# ESP32-P4-LP register map
Vendor: ESPRESSIF SYSTEMS (SHANGHAI) CO., LTD.; Series: ESP32 P-Series; File version: 3
CPU: RV32IMAC r0p0, little endian, no MPU, no FPU, 0 interrupt priority bits
Address unit: 32 bits
Registers are 32-bit, read-write, reset 0x0 unless marked. A register's access mark holds for its fields unless they carry their own. Offsets are from the block's base; [hi:lo] are bit positions.

## LP_ADC — Low-power Analog to Digital Converter
Base 0x50127000
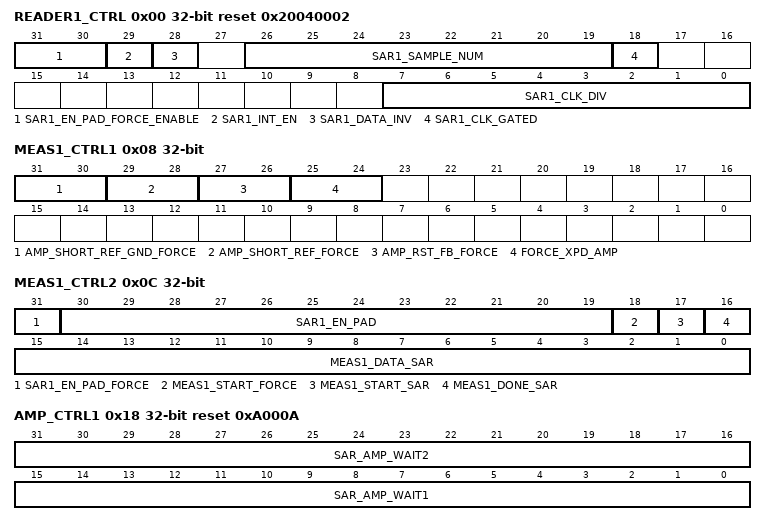
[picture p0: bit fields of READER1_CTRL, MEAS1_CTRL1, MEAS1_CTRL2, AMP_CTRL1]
0x00 READER1_CTRL reset 0x20040002 — Control the read operation of ADC1.
  [31:30] SAR1_EN_PAD_FORCE_ENABLE — Force enable adc en_pad to analog circuit 2'b11: force enable .
  [29] SAR1_INT_EN — Enable saradc1 to send out interrupt.
  [28] SAR1_DATA_INV — Invert SAR ADC1 data.
  [26:19] SAR1_SAMPLE_NUM
  [18] SAR1_CLK_GATED
  [7:0] SAR1_CLK_DIV — Clock divider.
0x04 READER1_STATUS ro reset 0x20000000
  [31:0] SAR1_READER_STATUS
0x08 MEAS1_CTRL1
  [31:30] AMP_SHORT_REF_GND_FORCE, [29:28] AMP_SHORT_REF_FORCE, [27:26] AMP_RST_FB_FORCE, [25:24] FORCE_XPD_AMP
0x0C MEAS1_CTRL2 access per field — ADC1 configuration registers.
  [31] SAR1_EN_PAD_FORCE rw — 1: SAR ADC1 pad enable bitmap is controlled by SW.
  [30:19] SAR1_EN_PAD rw — SAR ADC1 pad enable bitmap.
  [18] MEAS1_START_FORCE rw — 1: SAR ADC1 controller (in RTC) is started by SW.
  [17] MEAS1_START_SAR rw — SAR ADC1 controller (in RTC) starts conversion.
  [16] MEAS1_DONE_SAR ro — SAR ADC1 conversion done indication.
  [15:0] MEAS1_DATA_SAR ro — SAR ADC1 data.
0x10 MEAS1_MUX — SAR ADC1 MUX register.
  [31] SAR1_DIG_FORCE — 1: SAR ADC1 controlled by DIG ADC1 CTRL.
0x14 ATTEN1 reset 0xFFFFFFFF — ADC1 attenuation registers.
  [31:0] SAR1_ATTEN — 2-bit attenuation for each pad.
0x18 AMP_CTRL1 reset 0xA000A
  [31:16] SAR_AMP_WAIT2, [15:0] SAR_AMP_WAIT1
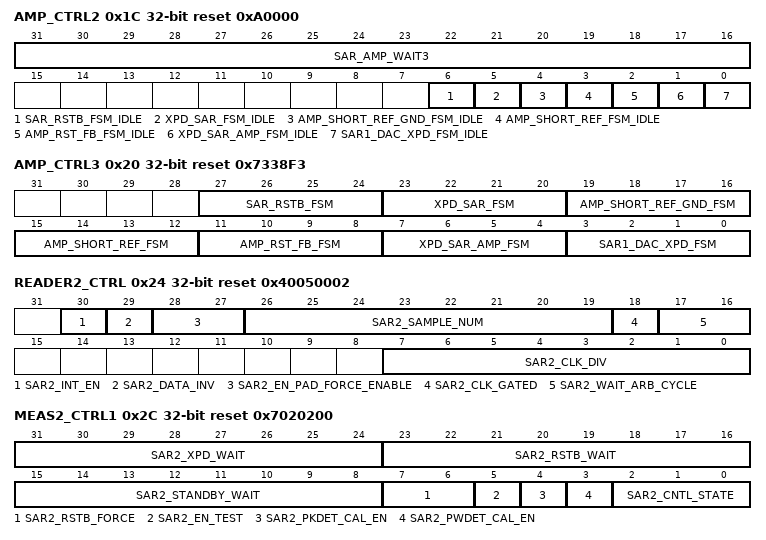
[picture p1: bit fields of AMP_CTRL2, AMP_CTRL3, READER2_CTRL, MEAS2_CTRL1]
0x1C AMP_CTRL2 reset 0xA0000
  [31:16] SAR_AMP_WAIT3, [6] SAR_RSTB_FSM_IDLE, [5] XPD_SAR_FSM_IDLE, [4] AMP_SHORT_REF_GND_FSM_IDLE, [3] AMP_SHORT_REF_FSM_IDLE, [2] AMP_RST_FB_FSM_IDLE, [1] XPD_SAR_AMP_FSM_IDLE, [0] SAR1_DAC_XPD_FSM_IDLE
0x20 AMP_CTRL3 reset 0x7338F3
  [27:24] SAR_RSTB_FSM, [23:20] XPD_SAR_FSM, [19:16] AMP_SHORT_REF_GND_FSM, [15:12] AMP_SHORT_REF_FSM, [11:8] AMP_RST_FB_FSM, [7:4] XPD_SAR_AMP_FSM, [3:0] SAR1_DAC_XPD_FSM
0x24 READER2_CTRL reset 0x40050002 — Control the read operation of ADC2.
  [30] SAR2_INT_EN — Enable saradc2 to send out interrupt.
  [29] SAR2_DATA_INV — Invert SAR ADC2 data.
  [28:27] SAR2_EN_PAD_FORCE_ENABLE — Force enable adc en_pad to analog circuit 2'b11: force enable .
  [26:19] SAR2_SAMPLE_NUM
  [18] SAR2_CLK_GATED
  [17:16] SAR2_WAIT_ARB_CYCLE — Wait arbit stable after sar_done.
  [7:0] SAR2_CLK_DIV — Clock divider.
0x28 READER2_STATUS ro
  [31:0] SAR2_READER_STATUS
0x2C MEAS2_CTRL1 access per field reset 0x7020200 — ADC2 configuration registers.
  [31:24] SAR2_XPD_WAIT rw
  [23:16] SAR2_RSTB_WAIT rw
  [15:8] SAR2_STANDBY_WAIT rw
  [7:6] SAR2_RSTB_FORCE rw
  [5] SAR2_EN_TEST rw
  [4] SAR2_PKDET_CAL_EN rw — RTC control pkdet enable.
  [3] SAR2_PWDET_CAL_EN rw — RTC control pwdet enable.
  [2:0] SAR2_CNTL_STATE ro — saradc2_cntl_fsm.
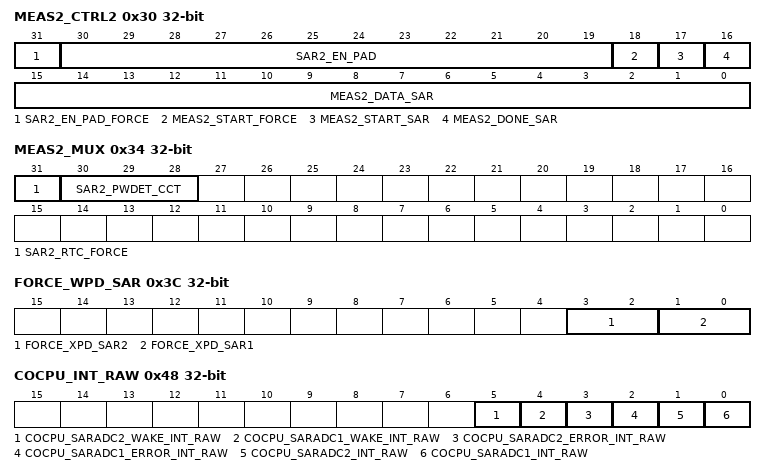
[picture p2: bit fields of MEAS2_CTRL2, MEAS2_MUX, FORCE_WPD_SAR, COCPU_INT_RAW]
0x30 MEAS2_CTRL2 access per field — ADC2 configuration registers.
  [31] SAR2_EN_PAD_FORCE rw — 1: SAR ADC2 pad enable bitmap is controlled by SW.
  [30:19] SAR2_EN_PAD rw — SAR ADC2 pad enable bitmap.
  [18] MEAS2_START_FORCE rw — 1: SAR ADC2 controller (in RTC) is started by SW.
  [17] MEAS2_START_SAR rw — SAR ADC2 controller (in RTC) starts conversion.
  [16] MEAS2_DONE_SAR ro — SAR ADC2 conversion done indication.
  [15:0] MEAS2_DATA_SAR ro — SAR ADC2 data.
0x34 MEAS2_MUX — SAR ADC2 MUX register.
  [31] SAR2_RTC_FORCE — In sleep, force to use rtc to control ADC.
  [30:28] SAR2_PWDET_CCT
0x38 ATTEN2 reset 0xFFFFFFFF — ADC1 attenuation registers.
  [31:0] SAR2_ATTEN — 2-bit attenuation for each pad.
0x3C FORCE_WPD_SAR — In sleep, force to use rtc to control ADC
  [3:2] FORCE_XPD_SAR2 — 2'b11:software control, force on. 2'b10:software control, force off. 2'b0x:hardware control.
  [1:0] FORCE_XPD_SAR1 — 2'b11:software control, force on. 2'b10:software control, force off. 2'b0x:hardware control.
0x40 MEAS_STATUS ro
  [7:0] SARADC_MEAS_STATUS
0x44 REG_CLKEN
  [0] CLK_EN
0x48 COCPU_INT_RAW — Interrupt raw registers.
  [5] COCPU_SARADC2_WAKE_INT_RAW — A wakeup event is triggered from ADC2, int raw.
  [4] COCPU_SARADC1_WAKE_INT_RAW — A wakeup event is triggered from ADC1, int raw.
  [3] COCPU_SARADC2_ERROR_INT_RAW — An errro occurs from ADC2, int raw.
  [2] COCPU_SARADC1_ERROR_INT_RAW — An errro occurs from ADC1, int raw.
  [1] COCPU_SARADC2_INT_RAW — ADC2 Conversion is done, int raw.
  [0] COCPU_SARADC1_INT_RAW — ADC1 Conversion is done, int raw.
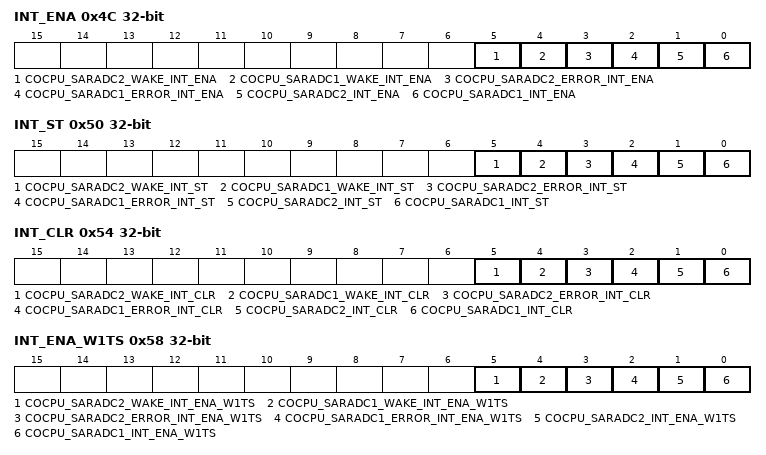
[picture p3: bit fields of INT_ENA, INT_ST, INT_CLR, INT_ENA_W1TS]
0x4C INT_ENA — Interrupt enable registers.
  [5] COCPU_SARADC2_WAKE_INT_ENA — A wakeup event is triggered from ADC2, int enable.
  [4] COCPU_SARADC1_WAKE_INT_ENA — A wakeup event is triggered from ADC1, int enable.
  [3] COCPU_SARADC2_ERROR_INT_ENA — An errro occurs from ADC2, int enable.
  [2] COCPU_SARADC1_ERROR_INT_ENA — An errro occurs from ADC1, int enable.
  [1] COCPU_SARADC2_INT_ENA — ADC2 Conversion is done, int enable.
  [0] COCPU_SARADC1_INT_ENA — ADC1 Conversion is done, int enable.
0x50 INT_ST ro — Interrupt status registers.
  [5] COCPU_SARADC2_WAKE_INT_ST — A wakeup event is triggered from ADC2, int status.
  [4] COCPU_SARADC1_WAKE_INT_ST — A wakeup event is triggered from ADC1, int status.
  [3] COCPU_SARADC2_ERROR_INT_ST — An errro occurs from ADC2, int status.
  [2] COCPU_SARADC1_ERROR_INT_ST — An errro occurs from ADC1, int status.
  [1] COCPU_SARADC2_INT_ST — ADC2 Conversion is done, int status.
  [0] COCPU_SARADC1_INT_ST — ADC1 Conversion is done, int status.
0x54 INT_CLR wo — Interrupt clear registers.
  [5] COCPU_SARADC2_WAKE_INT_CLR — A wakeup event is triggered from ADC2, int clear.
  [4] COCPU_SARADC1_WAKE_INT_CLR — A wakeup event is triggered from ADC1, int clear.
  [3] COCPU_SARADC2_ERROR_INT_CLR — An errro occurs from ADC2, int clear.
  [2] COCPU_SARADC1_ERROR_INT_CLR — An errro occurs from ADC1, int clear.
  [1] COCPU_SARADC2_INT_CLR — ADC2 Conversion is done, int clear.
  [0] COCPU_SARADC1_INT_CLR — ADC1 Conversion is done, int clear.
0x58 INT_ENA_W1TS wo — Interrupt enable assert registers.
  [5] COCPU_SARADC2_WAKE_INT_ENA_W1TS — A wakeup event is triggered from ADC2, write 1 to assert int enable.
  [4] COCPU_SARADC1_WAKE_INT_ENA_W1TS — A wakeup event is triggered from ADC1, write 1 to assert int enable.
  [3] COCPU_SARADC2_ERROR_INT_ENA_W1TS — An errro occurs from ADC2, write 1 to assert int enable.
  [2] COCPU_SARADC1_ERROR_INT_ENA_W1TS — An errro occurs from ADC1, write 1 to assert int enable.
  [1] COCPU_SARADC2_INT_ENA_W1TS — ADC2 Conversion is done, write 1 to assert int enable.
  [0] COCPU_SARADC1_INT_ENA_W1TS — ADC1 Conversion is done, write 1 to assert int enable.
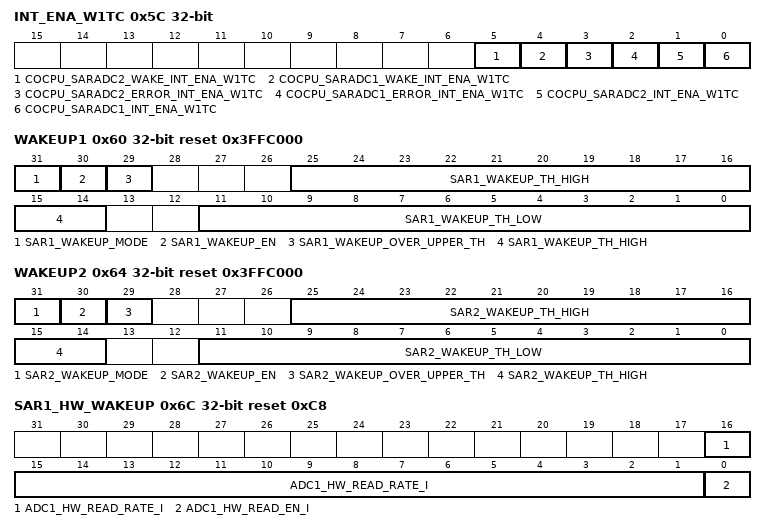
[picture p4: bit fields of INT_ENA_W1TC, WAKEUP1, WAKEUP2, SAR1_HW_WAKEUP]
0x5C INT_ENA_W1TC wo — Interrupt enable deassert registers.
  [5] COCPU_SARADC2_WAKE_INT_ENA_W1TC — A wakeup event is triggered from ADC2, write 1 to deassert int enable.
  [4] COCPU_SARADC1_WAKE_INT_ENA_W1TC — A wakeup event is triggered from ADC1, write 1 to deassert int enable.
  [3] COCPU_SARADC2_ERROR_INT_ENA_W1TC — An errro occurs from ADC2, write 1 to deassert int enable.
  [2] COCPU_SARADC1_ERROR_INT_ENA_W1TC — An errro occurs from ADC1, write 1 to deassert int enable.
  [1] COCPU_SARADC2_INT_ENA_W1TC — ADC2 Conversion is done, write 1 to deassert int enable.
  [0] COCPU_SARADC1_INT_ENA_W1TC — ADC1 Conversion is done, write 1 to deassert int enable.
0x60 WAKEUP1 access per field reset 0x3FFC000 — ADC1 wakeup configuration registers.
  [31] SAR1_WAKEUP_MODE rw — 0:absolute value comparison mode. 1: relative value comparison mode.
  [30] SAR1_WAKEUP_EN rw — Wakeup function enable.
  [29] SAR1_WAKEUP_OVER_UPPER_TH ro — Indicates that this wakeup event arose from exceeding upper threshold.
  [25:14] SAR1_WAKEUP_TH_HIGH rw — Upper threshold.
  [11:0] SAR1_WAKEUP_TH_LOW rw — Lower threshold.
0x64 WAKEUP2 access per field reset 0x3FFC000 — ADC2 wakeup configuration registers.
  [31] SAR2_WAKEUP_MODE rw — 0:absolute value comparison mode. 1: relative value comparison mode.
  [30] SAR2_WAKEUP_EN rw — Wakeup function enable.
  [29] SAR2_WAKEUP_OVER_UPPER_TH ro — Indicates that this wakeup event arose from exceeding upper threshold.
  [25:14] SAR2_WAKEUP_TH_HIGH rw — Upper threshold.
  [11:0] SAR2_WAKEUP_TH_LOW rw — Lower threshold.
0x68 WAKEUP_SEL — Wakeup source select register.
  [0] SAR_WAKEUP_SEL — 0: ADC1. 1: ADC2.
0x6C SAR1_HW_WAKEUP reset 0xC8 — Hardware automatic sampling registers for wakeup function.
  [16:1] ADC1_HW_READ_RATE_I — Hardware automatic sampling rate.
  [0] ADC1_HW_READ_EN_I — Enable hardware automatic sampling.
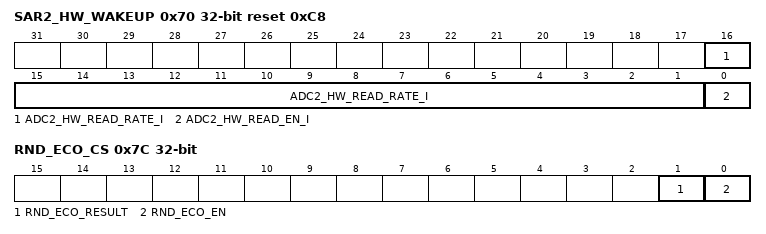
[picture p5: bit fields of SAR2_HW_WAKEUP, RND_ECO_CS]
0x70 SAR2_HW_WAKEUP reset 0xC8 — Hardware automatic sampling registers for wakeup function.
  [16:1] ADC2_HW_READ_RATE_I — Hardware automatic sampling rate.
  [0] ADC2_HW_READ_EN_I — Enable hardware automatic sampling.
0x74 RND_ECO_LOW
0x78 RND_ECO_HIGH reset 0xFFFFFFFF
0x7C RND_ECO_CS access per field
  [1] RND_ECO_RESULT ro, [0] RND_ECO_EN rw
